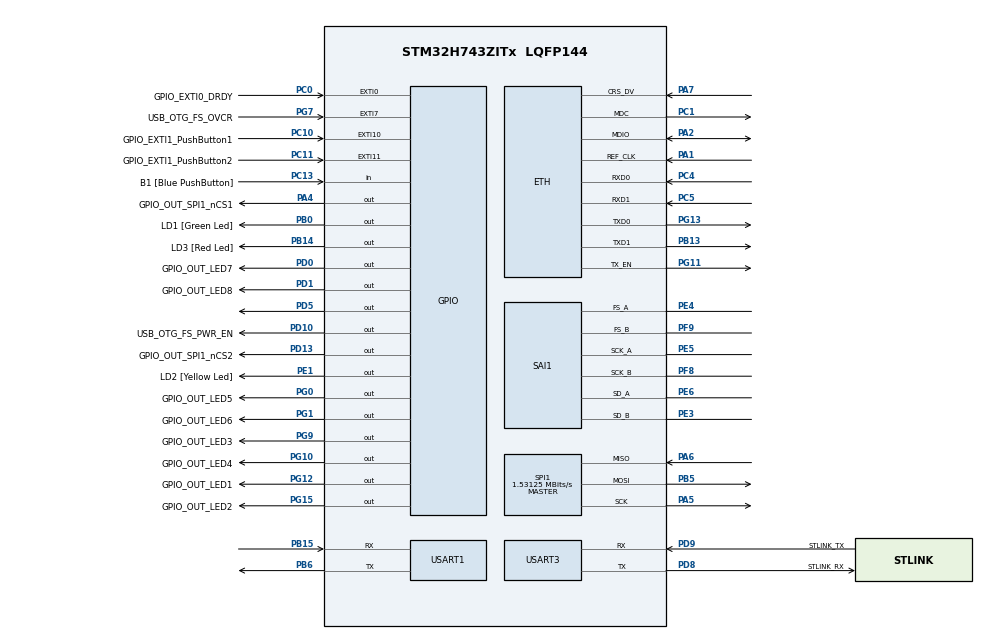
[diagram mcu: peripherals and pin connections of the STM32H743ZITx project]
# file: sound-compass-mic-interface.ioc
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CORTEX_M7.AccessPermission_S-Cortex_Memory_Protection_Unit_Region1_Settings_S=MPU_REGION_FULL_ACCESS
CORTEX_M7.AccessPermission_S-Cortex_Memory_Protection_Unit_Region2_Settings_S=MPU_REGION_FULL_ACCESS
CORTEX_M7.AccessPermission_S-Cortex_Memory_Protection_Unit_Region3_Settings_S=MPU_REGION_FULL_ACCESS
CORTEX_M7.BaseAddress_S-Cortex_Memory_Protection_Unit_Region1_Settings_S=0x30020000
CORTEX_M7.BaseAddress_S-Cortex_Memory_Protection_Unit_Region2_Settings_S=0x30040000
CORTEX_M7.BaseAddress_S-Cortex_Memory_Protection_Unit_Region3_Settings_S=0x38000000
CORTEX_M7.CPU_DCache=Enabled
CORTEX_M7.CPU_ICache=Enabled
CORTEX_M7.DisableExec_S-Cortex_Memory_Protection_Unit_Region1_Settings_S=MPU_INSTRUCTION_ACCESS_DISABLE
CORTEX_M7.DisableExec_S-Cortex_Memory_Protection_Unit_Region2_Settings_S=MPU_INSTRUCTION_ACCESS_DISABLE
CORTEX_M7.DisableExec_S-Cortex_Memory_Protection_Unit_Region3_Settings_S=MPU_INSTRUCTION_ACCESS_DISABLE
CORTEX_M7.Enable_S-Cortex_Memory_Protection_Unit_Region1_Settings_S=MPU_REGION_ENABLE
CORTEX_M7.Enable_S-Cortex_Memory_Protection_Unit_Region2_Settings_S=MPU_REGION_ENABLE
CORTEX_M7.Enable_S-Cortex_Memory_Protection_Unit_Region3_Settings_S=MPU_REGION_ENABLE
CORTEX_M7.Enable_S-Cortex_Memory_Protection_Unit_Region4_Settings_S=__NULL
CORTEX_M7.IsBufferable_S-Cortex_Memory_Protection_Unit_Region2_Settings_S=MPU_ACCESS_BUFFERABLE
CORTEX_M7.IsBufferable_S-Cortex_Memory_Protection_Unit_Region3_Settings_S=MPU_ACCESS_BUFFERABLE
CORTEX_M7.IsShareable_S-Cortex_Memory_Protection_Unit_Region2_Settings_S=MPU_ACCESS_SHAREABLE
CORTEX_M7.IsShareable_S-Cortex_Memory_Protection_Unit_Region3_Settings_S=MPU_ACCESS_SHAREABLE
CORTEX_M7.Size_S-Cortex_Memory_Protection_Unit_Region1_Settings_S=MPU_REGION_SIZE_128KB
CORTEX_M7.Size_S-Cortex_Memory_Protection_Unit_Region2_Settings_S=MPU_REGION_SIZE_512B
CORTEX_M7.Size_S-Cortex_Memory_Protection_Unit_Region3_Settings_S=MPU_REGION_SIZE_64KB
CORTEX_M7.TypeExtField_S-Cortex_Memory_Protection_Unit_Region1_Settings_S=MPU_TEX_LEVEL1
CORTEX_M7.default_mode_Activation=1
Dma.Request0=SPI1_RX
Dma.Request1=SPI1_TX
Dma.Request2=SAI1_A
Dma.Request3=SAI1_B
Dma.SAI1_A.2.Direction=DMA_PERIPH_TO_MEMORY
Dma.SAI1_A.2.EventEnable=DISABLE
Dma.SAI1_A.2.FIFOMode=DMA_FIFOMODE_ENABLE
Dma.SAI1_A.2.FIFOThreshold=DMA_FIFO_THRESHOLD_FULL
Dma.SAI1_A.2.Instance=DMA1_Stream2
Dma.SAI1_A.2.MemBurst=DMA_MBURST_SINGLE
Dma.SAI1_A.2.MemDataAlignment=DMA_MDATAALIGN_WORD
Dma.SAI1_A.2.MemInc=DMA_MINC_ENABLE
Dma.SAI1_A.2.Mode=DMA_CIRCULAR
Dma.SAI1_A.2.PeriphBurst=DMA_PBURST_INC4
Dma.SAI1_A.2.PeriphDataAlignment=DMA_PDATAALIGN_WORD
Dma.SAI1_A.2.PeriphInc=DMA_PINC_DISABLE
Dma.SAI1_A.2.Polarity=HAL_DMAMUX_REQ_GEN_RISING
Dma.SAI1_A.2.Priority=DMA_PRIORITY_LOW
Dma.SAI1_A.2.RequestNumber=1
Dma.SAI1_A.2.SignalID=NONE
Dma.SAI1_A.2.SyncEnable=DISABLE
Dma.SAI1_A.2.SyncPolarity=HAL_DMAMUX_SYNC_NO_EVENT
Dma.SAI1_A.2.SyncRequestNumber=1
Dma.SAI1_A.2.SyncSignalID=NONE
Dma.SAI1_B.3.Direction=DMA_PERIPH_TO_MEMORY
Dma.SAI1_B.3.EventEnable=DISABLE
Dma.SAI1_B.3.FIFOMode=DMA_FIFOMODE_ENABLE
Dma.SAI1_B.3.FIFOThreshold=DMA_FIFO_THRESHOLD_FULL
Dma.SAI1_B.3.Instance=DMA1_Stream3
Dma.SAI1_B.3.MemBurst=DMA_MBURST_SINGLE
Dma.SAI1_B.3.MemDataAlignment=DMA_MDATAALIGN_WORD
Dma.SAI1_B.3.MemInc=DMA_MINC_ENABLE
Dma.SAI1_B.3.Mode=DMA_CIRCULAR
Dma.SAI1_B.3.PeriphBurst=DMA_PBURST_INC4
Dma.SAI1_B.3.PeriphDataAlignment=DMA_PDATAALIGN_WORD
Dma.SAI1_B.3.PeriphInc=DMA_PINC_DISABLE
Dma.SAI1_B.3.Polarity=HAL_DMAMUX_REQ_GEN_RISING
Dma.SAI1_B.3.Priority=DMA_PRIORITY_LOW
Dma.SAI1_B.3.RequestNumber=1
Dma.SAI1_B.3.SignalID=NONE
Dma.SAI1_B.3.SyncEnable=DISABLE
Dma.SAI1_B.3.SyncPolarity=HAL_DMAMUX_SYNC_NO_EVENT
Dma.SAI1_B.3.SyncRequestNumber=1
Dma.SAI1_B.3.SyncSignalID=NONE
Dma.SPI1_RX.0.Direction=DMA_PERIPH_TO_MEMORY
Dma.SPI1_RX.0.EventEnable=DISABLE
Dma.SPI1_RX.0.FIFOMode=DMA_FIFOMODE_DISABLE
Dma.SPI1_RX.0.Instance=DMA1_Stream0
Dma.SPI1_RX.0.MemDataAlignment=DMA_MDATAALIGN_BYTE
Dma.SPI1_RX.0.MemInc=DMA_MINC_ENABLE
Dma.SPI1_RX.0.Mode=DMA_CIRCULAR
Dma.SPI1_RX.0.PeriphDataAlignment=DMA_PDATAALIGN_BYTE
Dma.SPI1_RX.0.PeriphInc=DMA_PINC_DISABLE
Dma.SPI1_RX.0.Polarity=HAL_DMAMUX_REQ_GEN_RISING
Dma.SPI1_RX.0.Priority=DMA_PRIORITY_HIGH
Dma.SPI1_RX.0.RequestNumber=1
Dma.SPI1_RX.0.SignalID=NONE
Dma.SPI1_RX.0.SyncEnable=DISABLE
Dma.SPI1_RX.0.SyncPolarity=HAL_DMAMUX_SYNC_NO_EVENT
Dma.SPI1_RX.0.SyncRequestNumber=1
Dma.SPI1_RX.0.SyncSignalID=NONE
Dma.SPI1_TX.1.Direction=DMA_MEMORY_TO_PERIPH
Dma.SPI1_TX.1.EventEnable=DISABLE
Dma.SPI1_TX.1.FIFOMode=DMA_FIFOMODE_DISABLE
Dma.SPI1_TX.1.Instance=DMA1_Stream1
Dma.SPI1_TX.1.MemDataAlignment=DMA_MDATAALIGN_BYTE
Dma.SPI1_TX.1.MemInc=DMA_MINC_ENABLE
Dma.SPI1_TX.1.Mode=DMA_CIRCULAR
Dma.SPI1_TX.1.PeriphDataAlignment=DMA_PDATAALIGN_BYTE
Dma.SPI1_TX.1.PeriphInc=DMA_PINC_DISABLE
Dma.SPI1_TX.1.Polarity=HAL_DMAMUX_REQ_GEN_RISING
Dma.SPI1_TX.1.Priority=DMA_PRIORITY_LOW
Dma.SPI1_TX.1.RequestNumber=1
Dma.SPI1_TX.1.SignalID=NONE
Dma.SPI1_TX.1.SyncEnable=DISABLE
Dma.SPI1_TX.1.SyncPolarity=HAL_DMAMUX_SYNC_NO_EVENT
Dma.SPI1_TX.1.SyncRequestNumber=1
Dma.SPI1_TX.1.SyncSignalID=NONE
ETH.MediaInterface=HAL_ETH_RMII_MODE
ETH.RxBuffLen=1536
ETH.RxDescAddress=0x30040000
ETH.TxDescAddress=0x30040200
FREERTOS.Tasks01=defaultTask,24,512,StartDefaultTask,Default,NULL,Static,defaultTaskBuffer,defaultTaskControlBlock
FREERTOS.configCHECK_FOR_STACK_OVERFLOW=1
FREERTOS.configMINIMAL_STACK_SIZE=512
FREERTOS.configTOTAL_HEAP_SIZE=30*1024
FREERTOS.configUSE_NEWLIB_REENTRANT=1
LWIP.BSP.number=1
LWIP.DEFAULT_THREAD_STACKSIZE=2048
LWIP.IP_ADDRESS=010.000.000.010
LWIP.LWIP_DBG_MIN_LEVEL=LWIP_DBG_LEVEL_SEVERE
LWIP.LWIP_DBG_TYPES_ON=LWIP_DBG_OFF
LWIP.LWIP_DHCP=0
LWIP.LWIP_RAM_HEAP_POINTER=0x30020000
LWIP.MEMP_NUM_TCP_PCB=2
LWIP.MEMP_NUM_TCP_PCB_LISTEN=2
LWIP.MEMP_NUM_UDP_PCB=2
LWIP.MEM_SIZE=131048
LWIP.NETMASK_ADDRESS=255.255.255.000
LWIP.PBUF_POOL_BUFSIZE=1474
LWIP.TCPIP_THREAD_STACKSIZE=2048
LWIP.TCP_MSS=1460
LWIP.TCP_SND_BUF=5840
LWIP.TCP_SND_QUEUELEN=16
LWIP.Version=v2.1.2_Cube
LWIP0.BSP.STBoard=false
LWIP0.BSP.api=BSP_COMPONENT_DRIVER
LWIP0.BSP.component=LAN8742
LWIP0.BSP.instance=LAN8742
LWIP0.BSP.name=Driver_PHY
LWIP0.BSP.semaphore=S_LAN8742
LWIP0.BSP.solution=LAN8742
Mcu.Family=STM32H7
Mcu.Name=STM32H743ZITx
Mcu.Package=LQFP144
Mcu.UserConstants=AUDIO_SAMPLE_RATE_HZ,48000;SYSTEM_CLOCK_HZ,480000000;SAI_DMA_BUFFER_SIZE,(NUM_MICS * BYTES_PER_SAMPLE);NUM_MICS,16;BYTES_PER_SAMPLE,4
NVIC.DMA1_Stream0_IRQn=true\:5\:0\:false\:false\:true\:true\:false\:true\:true
NVIC.DMA1_Stream1_IRQn=true\:5\:0\:false\:false\:true\:true\:false\:true\:true
NVIC.DMA1_Stream2_IRQn=true\:5\:0\:false\:false\:true\:true\:false\:true\:true
NVIC.DMA1_Stream3_IRQn=true\:5\:0\:false\:false\:true\:true\:false\:true\:true
NVIC.ETH_IRQn=true\:5\:0\:true\:false\:true\:true\:true\:true\:true
NVIC.EXTI0_IRQn=true\:5\:0\:false\:false\:true\:true\:true\:true\:true
NVIC.EXTI15_10_IRQn=true\:5\:0\:false\:false\:true\:true\:true\:true\:true
NVIC.EXTI9_5_IRQn=true\:5\:0\:false\:false\:true\:true\:true\:true\:true
NVIC.PriorityGroup=NVIC_PRIORITYGROUP_4
NVIC.SPI1_IRQn=true\:5\:0\:false\:false\:true\:true\:false\:true\:true
NVIC.TIM6_DAC_IRQn=true\:15\:0\:false\:false\:true\:false\:false\:true\:true
NVIC.TimeBase=TIM6_DAC_IRQn
NVIC.TimeBaseIP=TIM6
PA1.GPIO_Speed=GPIO_SPEED_FREQ_VERY_HIGH
PA1.Mode=RMII
PA1.Signal=ETH_REF_CLK
PA12.Signal=USB_OTG_FS_DP
PA2.GPIO_Speed=GPIO_SPEED_FREQ_VERY_HIGH
PA2.Mode=RMII
PA2.Signal=ETH_MDIO
PA4.GPIO_Label=GPIO_OUT_SPI1_nCS1
PA4.Signal=GPIO_Output
PA5.GPIO_Speed=GPIO_SPEED_FREQ_VERY_HIGH
PA5.Mode=Full_Duplex_Master
PA5.Signal=SPI1_SCK
PA6.GPIO_Speed=GPIO_SPEED_FREQ_VERY_HIGH
PA6.Mode=Full_Duplex_Master
PA6.Signal=SPI1_MISO
PA7.GPIO_Speed=GPIO_SPEED_FREQ_VERY_HIGH
PA7.Mode=RMII
PA7.Signal=ETH_CRS_DV
PA9.Signal=USB_OTG_FS_VBUS
PB0.GPIO_Label=LD1 [Green Led]
PB0.Signal=GPIO_Output
PB13.GPIO_Speed=GPIO_SPEED_FREQ_VERY_HIGH
PB13.Mode=RMII
PB13.Signal=ETH_TXD1
PB14.GPIO_Label=LD3 [Red Led]
PB14.Signal=GPIO_Output
PB15.Mode=Asynchronous
PB15.Signal=USART1_RX
PB5.GPIO_Speed=GPIO_SPEED_FREQ_VERY_HIGH
PB5.Mode=Full_Duplex_Master
PB5.Signal=SPI1_MOSI
PB6.Mode=Asynchronous
PB6.Signal=USART1_TX
PC0.GPIO_Label=GPIO_EXTI0_DRDY
PC0.Signal=GPXTI0
PC1.GPIO_Speed=GPIO_SPEED_FREQ_VERY_HIGH
PC1.Mode=RMII
PC1.Signal=ETH_MDC
PC10.GPIO_Label=GPIO_EXTI1_PushButton1
PC10.GPIO_ModeDefaultEXTI=GPIO_MODE_IT_FALLING
PC10.GPIO_PuPd=GPIO_PULLUP
PC10.Signal=GPXTI10
PC11.GPIO_Label=GPIO_EXTI1_PushButton2
PC11.GPIO_ModeDefaultEXTI=GPIO_MODE_IT_FALLING
PC11.GPIO_PuPd=GPIO_PULLUP
PC11.Signal=GPXTI11
PC12.Signal=SPI3_MOSI
PC13.GPIO_Label=B1 [Blue PushButton]
PC13.Signal=GPIO_Input
PC14-OSC32_IN\ (OSC32_IN).Signal=RCC_OSC32_IN
PC15-OSC32_OUT\ (OSC32_OUT).Signal=RCC_OSC32_OUT
PC4.GPIO_Speed=GPIO_SPEED_FREQ_VERY_HIGH
PC4.Mode=RMII
PC4.Signal=ETH_RXD0
PC5.GPIO_Speed=GPIO_SPEED_FREQ_VERY_HIGH
PC5.Mode=RMII
PC5.Signal=ETH_RXD1
PD0.GPIO_Label=GPIO_OUT_LED7
PD0.Signal=GPIO_Output
PD1.GPIO_Label=GPIO_OUT_LED8
PD1.Signal=GPIO_Output
PD10.GPIO_Label=USB_OTG_FS_PWR_EN
PD10.Signal=GPIO_Output
PD13.GPIO_Label=GPIO_OUT_SPI1_nCS2
PD13.Signal=GPIO_Output
PD5.GPIO_ModeDefaultOutputPP=GPIO_MODE_OUTPUT_PP
PD5.GPIO_PuPd=GPIO_NOPULL
PD5.GPIO_Speed=GPIO_SPEED_FREQ_LOW
PD5.PinState=GPIO_PIN_SET
PD5.Signal=GPIO_Output
PD8.GPIO_Label=STLINK_RX
PD8.Mode=Asynchronous
PD8.Signal=USART3_TX
PD9.GPIO_Label=STLINK_TX
PD9.Mode=Asynchronous
PD9.Signal=USART3_RX
PE1.GPIO_Label=LD2 [Yellow Led]
PE1.Signal=GPIO_Output
PE3.Mode=SAI_B_AsyncSlave
PE3.Signal=SAI1_SD_B
PE4.Mode=SAI_A_AsyncSlave
PE4.Signal=SAI1_FS_A
PE5.Mode=SAI_A_AsyncSlave
PE5.Signal=SAI1_SCK_A
PE6.Mode=SAI_A_AsyncSlave
PE6.Signal=SAI1_SD_A
PF8.Mode=SAI_B_AsyncSlave
PF8.Signal=SAI1_SCK_B
PF9.Mode=SAI_B_AsyncSlave
PF9.Signal=SAI1_FS_B
PG0.GPIO_Label=GPIO_OUT_LED5
PG0.Signal=GPIO_Output
PG1.GPIO_Label=GPIO_OUT_LED6
PG1.Signal=GPIO_Output
PG10.GPIO_Label=GPIO_OUT_LED4
PG10.Signal=GPIO_Output
PG11.GPIO_Speed=GPIO_SPEED_FREQ_VERY_HIGH
PG11.Mode=RMII
PG11.Signal=ETH_TX_EN
PG12.GPIO_Label=GPIO_OUT_LED1
PG12.Signal=GPIO_Output
PG13.GPIO_Speed=GPIO_SPEED_FREQ_VERY_HIGH
PG13.Mode=RMII
PG13.Signal=ETH_TXD0
PG15.GPIO_Label=GPIO_OUT_LED2
PG15.Signal=GPIO_Output
PG7.GPIO_Label=USB_OTG_FS_OVCR
PG7.Signal=GPXTI7
PG9.GPIO_Label=GPIO_OUT_LED3
PG9.GPIO_ModeDefaultOutputPP=GPIO_MODE_OUTPUT_PP
PG9.GPIO_PuPd=GPIO_NOPULL
PG9.GPIO_Speed=GPIO_SPEED_FREQ_LOW
PG9.PinState=GPIO_PIN_SET
PG9.Signal=GPIO_Output
PH0-OSC_IN\ (PH0).Signal=RCC_OSC_IN
PH1-OSC_OUT\ (PH1).Signal=RCC_OSC_OUT
ProjectManager.HeapSize=0x200
ProjectManager.StackSize=0x400
ProjectManager.TargetToolchain=STM32CubeIDE
RCC.ADCFreq_Value=100000000
RCC.APB1Freq_Value=120000000
RCC.APB2Freq_Value=120000000
RCC.APB3Freq_Value=120000000
RCC.APB4Freq_Value=120000000
RCC.CortexFreq_Value=480000000
RCC.D1PPRE=RCC_APB3_DIV2
RCC.D2PPRE1=RCC_APB1_DIV2
RCC.D2PPRE2=RCC_APB2_DIV2
RCC.D3PPRE=RCC_APB4_DIV2
RCC.DIVN1=480
RCC.DIVN2=100
RCC.DIVN3=98
RCC.DIVP3=4
RCC.HCLKFreq_Value=240000000
RCC.HPRE=RCC_HCLK_DIV2
RCC.ProductRev=revV
RCC.RCC_MCO2Source=RCC_MCO2SOURCE_CSICLK
RCC.RCC_MCODiv1=RCC_MCODIV_2
RCC.SAI1CLockSelection=RCC_SAI1CLKSOURCE_PLL2
RCC.SPI123CLockSelection=RCC_SPI123CLKSOURCE_PLL3
RCC.SYSCLKFreq_VALUE=480000000
RCC.SYSCLKSource=RCC_SYSCLKSOURCE_PLLCLK
RCC.USBFreq_Value=480000000
SAI1.ActiveFrameLength-SAI_B_AsyncSlave=1
SAI1.DataSize-SAI_A_AsyncSlave=SAI_DATASIZE_32
SAI1.DataSize-SAI_B_AsyncSlave=SAI_DATASIZE_32
SAI1.FIFOThreshold-SAI_A_AsyncSlave=SAI_FIFOTHRESHOLD_FULL
SAI1.FIFOThreshold-SAI_B_AsyncSlave=SAI_FIFOTHRESHOLD_FULL
SAI1.FSOffset-SAI_A_AsyncSlave=SAI_FS_BEFOREFIRSTBIT
SAI1.FSOffset-SAI_B_AsyncSlave=SAI_FS_BEFOREFIRSTBIT
SAI1.FSPolarity-SAI_A_AsyncSlave=SAI_FS_ACTIVE_HIGH
SAI1.FSPolarity-SAI_B_AsyncSlave=SAI_FS_ACTIVE_HIGH
SAI1.FrameLength-SAI_A_AsyncSlave=128
SAI1.FrameLength-SAI_B_AsyncSlave=128
SAI1.Instance-SAI_A_AsyncSlave=SAI$Index_Block_A
SAI1.Instance-SAI_B_AsyncSlave=SAI$Index_Block_B
SAI1.SlotActive-SAI_A_AsyncSlave=0x0000FFFF
SAI1.SlotActive-SAI_B_AsyncSlave=0x0000FFFF
SAI1.SlotNumber-SAI_A_AsyncSlave=4
SAI1.SlotNumber-SAI_B_AsyncSlave=4
SAI1.VirtualMode-SAI_A_AsyncSlave=VM_SLAVE
SAI1.VirtualMode-SAI_B_AsyncSlave=VM_SLAVE
SAI1.VirtualSlotActive-SAI_A_AsyncSlave=SAI_SLOTACTIVE_ALL
SAI1.VirtualSlotActive-SAI_B_AsyncSlave=SAI_SLOTACTIVE_ALL
SPI1.BaudRatePrescaler=SPI_BAUDRATEPRESCALER_32
SPI1.CalculateBaudRate=1.53125 MBits/s
SPI1.DataSize=SPI_DATASIZE_8BIT
SPI1.Direction=SPI_DIRECTION_2LINES
SPI1.Mode=SPI_MODE_MASTER
SPI1.VirtualType=VM_MASTER
USART1.VirtualMode-Asynchronous=VM_ASYNC
USART3.VirtualMode-Asynchronous=VM_ASYNC
VP_FREERTOS_VS_CMSIS_V2.Mode=CMSIS_V2
VP_LWIP_VS_Enabled.Mode=Enabled
VP_MEMORYMAP_VS_MEMORYMAP.Mode=CurAppReg
VP_SYS_VS_tim6.Mode=TIM6
board=NUCLEO-H743ZI2

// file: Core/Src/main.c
/* USER CODE BEGIN Header */
/**
  ******************************************************************************
  * @file           : main.c
  * @brief          : Main program body
  ******************************************************************************
  * @attention
  *
  * Copyright (c) 2022 STMicroelectronics.
  * All rights reserved.
  *
  * This software is licensed under terms that can be found in the LICENSE file
  * in the root directory of this software component.
  * If no LICENSE file comes with this software, it is provided AS-IS.
  *
  ******************************************************************************
  */
/* USER CODE END Header */
#include "main.h"
#include "cmsis_os.h"
#include "dma.h"
#include "lwip.h"
#include "memorymap.h"
#include "sai.h"
#include "spi.h"
#include "usart.h"
#include "gpio.h"

/* USER CODE BEGIN Includes */

#include "app/StartupApp_c.h"

/* USER CODE END Includes */

void SystemClock_Config(void);
void PeriphCommonClock_Config(void);
static void MPU_Config(void);
void MX_FREERTOS_Init(void);

int main(void)
{

  /* MPU Configuration--------------------------------------------------------*/
  MPU_Config();

  /* Enable the CPU Cache */

  /* Enable I-Cache---------------------------------------------------------*/
  SCB_EnableICache();

  /* Enable D-Cache---------------------------------------------------------*/
  SCB_EnableDCache();

  /* MCU Configuration--------------------------------------------------------*/

  /* Reset of all peripherals, Initializes the Flash interface and the Systick. */
  HAL_Init();

  /* Configure the system clock */
  SystemClock_Config();

  /* Configure the peripherals common clocks */
  PeriphCommonClock_Config();

  /* Initialize all configured peripherals */
  MX_GPIO_Init();
  MX_DMA_Init();
  MX_USART1_UART_Init();
  MX_USART3_UART_Init();
  MX_SPI1_Init();
  MX_SAI1_Init();

  /* Init scheduler */
  osKernelInitialize();

  /* Call init function for freertos objects (in cmsis_os2.c) */
  MX_FREERTOS_Init();

  /* Start scheduler */
  osKernelStart();

  /* We should never get here as control is now taken by the scheduler */

  /* Infinite loop */
  while (1)
  {

  }
}

void SystemClock_Config(void)
{
  RCC_OscInitTypeDef RCC_OscInitStruct = {0};
  RCC_ClkInitTypeDef RCC_ClkInitStruct = {0};

  /** Supply configuration update enable
  */
  HAL_PWREx_ConfigSupply(PWR_LDO_SUPPLY);

  /** Configure the main internal regulator output voltage
  */
  __HAL_PWR_VOLTAGESCALING_CONFIG(PWR_REGULATOR_VOLTAGE_SCALE1);

  while(!__HAL_PWR_GET_FLAG(PWR_FLAG_VOSRDY)) {}

  __HAL_RCC_SYSCFG_CLK_ENABLE();
  __HAL_PWR_VOLTAGESCALING_CONFIG(PWR_REGULATOR_VOLTAGE_SCALE0);

  while(!__HAL_PWR_GET_FLAG(PWR_FLAG_VOSRDY)) {}

  /** Initializes the RCC Oscillators according to the specified parameters
  * in the RCC_OscInitTypeDef structure.
  */
  RCC_OscInitStruct.OscillatorType = RCC_OSCILLATORTYPE_HSI;
  RCC_OscInitStruct.HSIState = RCC_HSI_DIV1;
  RCC_OscInitStruct.HSICalibrationValue = RCC_HSICALIBRATION_DEFAULT;
  RCC_OscInitStruct.PLL.PLLState = RCC_PLL_ON;
  RCC_OscInitStruct.PLL.PLLSource = RCC_PLLSOURCE_HSI;
  RCC_OscInitStruct.PLL.PLLM = 32;
  RCC_OscInitStruct.PLL.PLLN = 480;
  RCC_OscInitStruct.PLL.PLLP = 2;
  RCC_OscInitStruct.PLL.PLLQ = 2;
  RCC_OscInitStruct.PLL.PLLR = 2;
  RCC_OscInitStruct.PLL.PLLRGE = RCC_PLL1VCIRANGE_1;
  RCC_OscInitStruct.PLL.PLLVCOSEL = RCC_PLL1VCOWIDE;
  RCC_OscInitStruct.PLL.PLLFRACN = 0;
  if (HAL_RCC_OscConfig(&RCC_OscInitStruct) != HAL_OK)
  {
    Error_Handler();
  }

  /** Initializes the CPU, AHB and APB buses clocks
  */
  RCC_ClkInitStruct.ClockType = RCC_CLOCKTYPE_HCLK|RCC_CLOCKTYPE_SYSCLK
                              |RCC_CLOCKTYPE_PCLK1|RCC_CLOCKTYPE_PCLK2
                              |RCC_CLOCKTYPE_D3PCLK1|RCC_CLOCKTYPE_D1PCLK1;
  RCC_ClkInitStruct.SYSCLKSource = RCC_SYSCLKSOURCE_PLLCLK;
  RCC_ClkInitStruct.SYSCLKDivider = RCC_SYSCLK_DIV1;
  RCC_ClkInitStruct.AHBCLKDivider = RCC_HCLK_DIV2;
  RCC_ClkInitStruct.APB3CLKDivider = RCC_APB3_DIV2;
  RCC_ClkInitStruct.APB1CLKDivider = RCC_APB1_DIV2;
  RCC_ClkInitStruct.APB2CLKDivider = RCC_APB2_DIV2;
  RCC_ClkInitStruct.APB4CLKDivider = RCC_APB4_DIV2;

  if (HAL_RCC_ClockConfig(&RCC_ClkInitStruct, FLASH_LATENCY_4) != HAL_OK)
  {
    Error_Handler();
  }
}

void PeriphCommonClock_Config(void)
{
  RCC_PeriphCLKInitTypeDef PeriphClkInitStruct = {0};

  /** Initializes the peripherals clock
  */
  PeriphClkInitStruct.PeriphClockSelection = RCC_PERIPHCLK_SAI1;
  PeriphClkInitStruct.PLL2.PLL2M = 32;
  PeriphClkInitStruct.PLL2.PLL2N = 100;
  PeriphClkInitStruct.PLL2.PLL2P = 2;
  PeriphClkInitStruct.PLL2.PLL2Q = 2;
  PeriphClkInitStruct.PLL2.PLL2R = 2;
  PeriphClkInitStruct.PLL2.PLL2RGE = RCC_PLL2VCIRANGE_1;
  PeriphClkInitStruct.PLL2.PLL2VCOSEL = RCC_PLL2VCOWIDE;
  PeriphClkInitStruct.PLL2.PLL2FRACN = 0;
  PeriphClkInitStruct.Sai1ClockSelection = RCC_SAI1CLKSOURCE_PLL2;
  if (HAL_RCCEx_PeriphCLKConfig(&PeriphClkInitStruct) != HAL_OK)
  {
    Error_Handler();
  }
}

 /* MPU Configuration */

void MPU_Config(void)
{
  MPU_Region_InitTypeDef MPU_InitStruct = {0};

  /* Disables the MPU */
  HAL_MPU_Disable();

  /** Initializes and configures the Region and the memory to be protected
  */
  MPU_InitStruct.Enable = MPU_REGION_ENABLE;
  MPU_InitStruct.Number = MPU_REGION_NUMBER0;
  MPU_InitStruct.BaseAddress = 0x0;
  MPU_InitStruct.Size = MPU_REGION_SIZE_4GB;
  MPU_InitStruct.SubRegionDisable = 0x87;
  MPU_InitStruct.TypeExtField = MPU_TEX_LEVEL0;
  MPU_InitStruct.AccessPermission = MPU_REGION_NO_ACCESS;
  MPU_InitStruct.DisableExec = MPU_INSTRUCTION_ACCESS_DISABLE;
  MPU_InitStruct.IsShareable = MPU_ACCESS_SHAREABLE;
  MPU_InitStruct.IsCacheable = MPU_ACCESS_NOT_CACHEABLE;
  MPU_InitStruct.IsBufferable = MPU_ACCESS_NOT_BUFFERABLE;

  HAL_MPU_ConfigRegion(&MPU_InitStruct);

  /** Initializes and configures the Region and the memory to be protected
  */
  MPU_InitStruct.Number = MPU_REGION_NUMBER1;
  MPU_InitStruct.BaseAddress = 0x30020000;
  MPU_InitStruct.Size = MPU_REGION_SIZE_128KB;
  MPU_InitStruct.SubRegionDisable = 0x0;
  MPU_InitStruct.TypeExtField = MPU_TEX_LEVEL1;
  MPU_InitStruct.AccessPermission = MPU_REGION_FULL_ACCESS;
  MPU_InitStruct.IsShareable = MPU_ACCESS_NOT_SHAREABLE;

  HAL_MPU_ConfigRegion(&MPU_InitStruct);

  /** Initializes and configures the Region and the memory to be protected
  */
  MPU_InitStruct.Number = MPU_REGION_NUMBER2;
  MPU_InitStruct.BaseAddress = 0x30040000;
  MPU_InitStruct.Size = MPU_REGION_SIZE_512B;
  MPU_InitStruct.TypeExtField = MPU_TEX_LEVEL0;
  MPU_InitStruct.IsShareable = MPU_ACCESS_SHAREABLE;
  MPU_InitStruct.IsBufferable = MPU_ACCESS_BUFFERABLE;

  HAL_MPU_ConfigRegion(&MPU_InitStruct);

  /** Initializes and configures the Region and the memory to be protected
  */
  MPU_InitStruct.Number = MPU_REGION_NUMBER3;
  MPU_InitStruct.BaseAddress = 0x38000000;
  MPU_InitStruct.Size = MPU_REGION_SIZE_64KB;

  HAL_MPU_ConfigRegion(&MPU_InitStruct);
  /* Enables the MPU */
  HAL_MPU_Enable(MPU_PRIVILEGED_DEFAULT);

}

void HAL_TIM_PeriodElapsedCallback(TIM_HandleTypeDef *htim)
{
  if (htim->Instance == TIM6) {
    HAL_IncTick();
  }
}

void Error_Handler(void)
{
  __disable_irq();
  while (1)
  {
  }
}

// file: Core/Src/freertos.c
/* USER CODE BEGIN Header */
/**
  ******************************************************************************
  * File Name          : freertos.c
  * Description        : Code for freertos applications
  ******************************************************************************
  * @attention
  *
  * Copyright (c) 2022 STMicroelectronics.
  * All rights reserved.
  *
  * This software is licensed under terms that can be found in the LICENSE file
  * in the root directory of this software component.
  * If no LICENSE file comes with this software, it is provided AS-IS.
  *
  ******************************************************************************
  */
/* USER CODE END Header */

#include "FreeRTOS.h"
#include "task.h"
#include "main.h"
#include "cmsis_os.h"

/* USER CODE BEGIN Includes */
#include "app/StartupApp_c.h"
/* USER CODE END Includes */

typedef StaticTask_t osStaticThreadDef_t;

/* Definitions for defaultTask */
osThreadId_t defaultTaskHandle;
uint32_t defaultTaskBuffer[ 512 ];
osStaticThreadDef_t defaultTaskControlBlock;
const osThreadAttr_t defaultTask_attributes = {
  .name = "defaultTask",
  .cb_mem = &defaultTaskControlBlock,
  .cb_size = sizeof(defaultTaskControlBlock),
  .stack_mem = &defaultTaskBuffer[0],
  .stack_size = sizeof(defaultTaskBuffer),
  .priority = (osPriority_t) osPriorityNormal,
};

void StartDefaultTask(void *argument);

extern void MX_LWIP_Init(void);
void MX_FREERTOS_Init(void); /* (MISRA C 2004 rule 8.1) */

/* Hook prototypes */
void vApplicationStackOverflowHook(xTaskHandle xTask, signed char *pcTaskName);

/* USER CODE BEGIN 4 */
void vApplicationStackOverflowHook(xTaskHandle xTask, signed char *pcTaskName)
{
   /* ETH_CODE: add breakpoint when stack oveflow is detected by FreeRTOS.
    * Useful for debugging issues.
    */
   __BKPT(0);
}
/* USER CODE END 4 */

void MX_FREERTOS_Init(void) {

  /* Create the thread(s) */
  /* creation of defaultTask */
  defaultTaskHandle = osThreadNew(StartDefaultTask, NULL, &defaultTask_attributes);

}

void StartDefaultTask(void *argument)
{
  /* init code for LWIP */
  MX_LWIP_Init();
  /* USER CODE BEGIN StartDefaultTask */

    executiveStart_c();
  /* Infinite loop */
  for(;;)
  {
    osDelay(1);
  }
  /* USER CODE END StartDefaultTask */
}
